# MSPM0G110X register map
Vendor: Texas Instruments; File version: This preliminary header file does not have a version number - build date: 2023-02-21 16:25:48
CPU: CM0 r0p1, little endian, MPU, no FPU, 3 interrupt priority bits
Registers are 32-bit, read-write, reset 0x0 unless marked. A register's access mark holds for its fields unless they carry their own. Offsets are from the block's base; [hi:lo] are bit positions; {n}, {i} and the like mark numbered series.

## TIMA0 — PERIPHERALREGION
Base 0x40860000
0x400 FSUB_0 — Subsciber Port 0
  [3:0] FSUB_0_CHANID — 0 = disconnected. 1-15 = connected to channelID = CHANID.
    0=FSUB_0_CHANID_UNCONNECTED (UNCONNECTED)
0x404 FSUB_1 — Subscriber Port 1
  [3:0] FSUB_1_CHANID — 0 = disconnected. 1-15 = connected to channelID = CHANID.
    0=FSUB_1_CHANID_UNCONNECTED (UNCONNECTED)
0x444 FPUB_0 — Publisher Port 0
  [3:0] FPUB_0_CHANID — 0 = disconnected. 1-15 = connected to channelID = CHANID.
    0=FPUB_0_CHANID_UNCONNECTED (UNCONNECTED)
0x448 FPUB_1 — Publisher Port 1
  [3:0] FPUB_1_CHANID — 0 = disconnected. 1-15 = connected to channelID = CHANID.
    0=FPUB_1_CHANID_UNCONNECTED (UNCONNECTED)
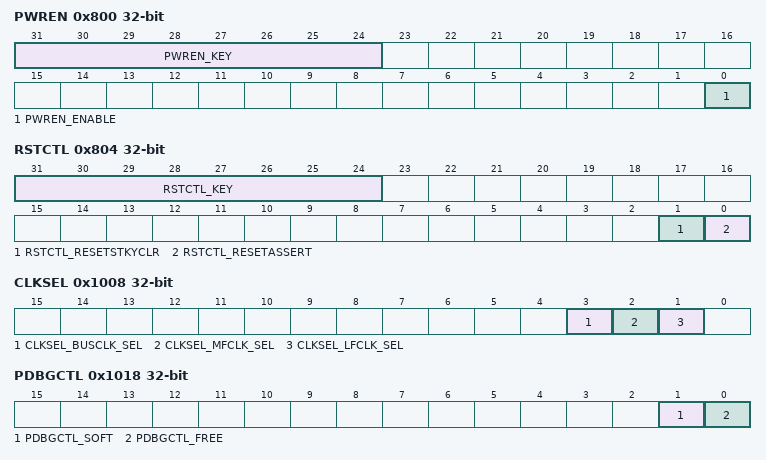
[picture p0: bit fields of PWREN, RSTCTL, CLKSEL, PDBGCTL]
0x800 PWREN — Power enable
  [31:24] PWREN_KEY wo — KEY to allow Power State Change
    38=PWREN_KEY_UNLOCK_W (_TO_UNLOCK_W_)
  [0] PWREN_ENABLE — Enable the power
    0=PWREN_ENABLE_DISABLE (DISABLE); 1=PWREN_ENABLE_ENABLE (ENABLE)
0x804 RSTCTL wo — Reset Control
  [31:24] RSTCTL_KEY — Unlock key
    177=RSTCTL_KEY_UNLOCK_W (_TO_UNLOCK_W_)
  [1] RSTCTL_RESETSTKYCLR — Clear the RESETSTKY bit in the STAT register
    0=RSTCTL_RESETSTKYCLR_NOP (NOP); 1=RSTCTL_RESETSTKYCLR_CLR (CLR)
  [0] RSTCTL_RESETASSERT — Assert reset to the peripheral
    0=RSTCTL_RESETASSERT_NOP (NOP); 1=RSTCTL_RESETASSERT_ASSERT (ASSERT)
0x814 STAT ro — Status Register
  [16] STAT_RESETSTKY — This bit indicates, if the peripheral was reset, since this bit was cleared by RESETSTKYCLR in the RSTCTL register
    0=STAT_RESETSTKY_NORES (NORES); 1=STAT_RESETSTKY_RESET (RESET)
0x1000 CLKDIV — Clock Divider
  [2:0] CLKDIV_RATIO — Selects divide ratio of module clock
    {v}=CLKDIV_RATIO_DIV_BY_{v+1} (DIV_BY_{v+1}) (v=0..7)
0x1008 CLKSEL — Clock Select for Ultra Low Power peripherals
  [3] CLKSEL_BUSCLK_SEL — Selects BUSCLK as clock source if enabled
    0=CLKSEL_BUSCLK_SEL_DISABLE (DISABLE); 1=CLKSEL_BUSCLK_SEL_ENABLE (ENABLE)
  [2] CLKSEL_MFCLK_SEL — Selects MFCLK as clock source if enabled
    0=CLKSEL_MFCLK_SEL_DISABLE (DISABLE); 1=CLKSEL_MFCLK_SEL_ENABLE (ENABLE)
  [1] CLKSEL_LFCLK_SEL — Selects LFCLK as clock source if enabled
    0=CLKSEL_LFCLK_SEL_DISABLE (DISABLE); 1=CLKSEL_LFCLK_SEL_ENABLE (ENABLE)
0x1018 PDBGCTL — Peripheral Debug Control
  [1] PDBGCTL_SOFT — Soft halt boundary control. This function is only available, if [FREE] is set to 'STOP'
    0=PDBGCTL_SOFT_IMMEDIATE (IMMEDIATE); 1=PDBGCTL_SOFT_DELAYED (DELAYED)
  [0] PDBGCTL_FREE — Free run control
    0=PDBGCTL_FREE_STOP (STOP); 1=PDBGCTL_FREE_RUN (RUN)
0x1020 IIDX ro — Interrupt index
  [7:0] IIDX_STAT — Interrupt index status
    0=IIDX_STAT_NO_INTR (NO_INTR); 1=IIDX_STAT_Z (Z); 2=IIDX_STAT_L (L); {v}=IIDX_STAT_CCD{v-5} (CCD{v-5}) (v=5..8); {v}=IIDX_STAT_CCU{v-9} (CCU{v-9}) (v=9..12); 13=IIDX_STAT_CCD4 (CCD4); 14=IIDX_STAT_CCD5 (CCD5); 15=IIDX_STAT_CCU4 (CCU4); 16=IIDX_STAT_CCU5 (CCU5); 25=IIDX_STAT_F (F); 26=IIDX_STAT_TOV (TOV); 27=IIDX_STAT_REPC (REPC); 28=IIDX_STAT_DC (DC); 29=IIDX_STAT_QEIERR (QEIERR)
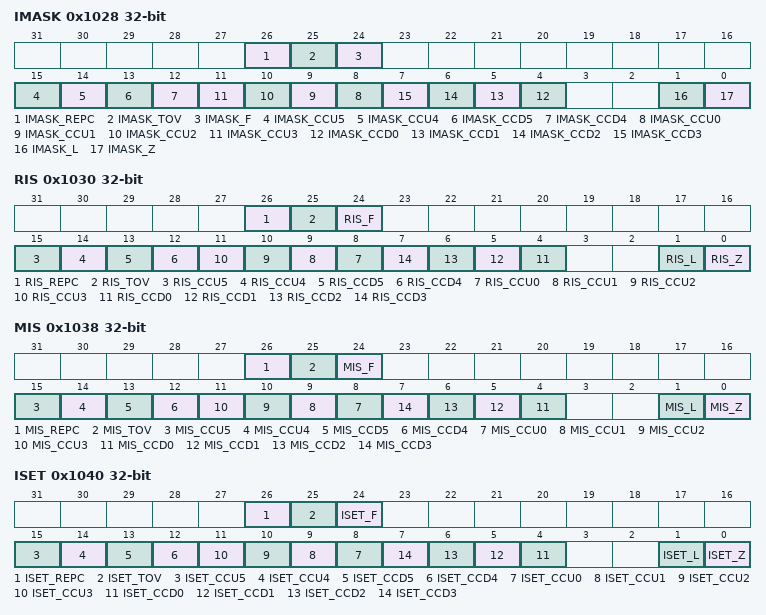
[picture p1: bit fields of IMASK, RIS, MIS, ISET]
0x1028 IMASK — Interrupt mask
  [26] IMASK_REPC — Repeat Counter Zero Event mask
    0=IMASK_REPC_CLR (CLR); 1=IMASK_REPC_SET (SET)
  [25] IMASK_TOV — Trigger Overflow Event mask
    0=IMASK_TOV_CLR (CLR); 1=IMASK_TOV_SET (SET)
  [24] IMASK_F — Fault Event mask
    0=IMASK_F_CLR (CLR); 1=IMASK_F_SET (SET)
  [15] IMASK_CCU5 — Compare UP event mask CCP5
    0=IMASK_CCU5_CLR (CLR); 1=IMASK_CCU5_SET (SET)
  [14] IMASK_CCU4 — Compare UP event mask CCP4
    0=IMASK_CCU4_CLR (CLR); 1=IMASK_CCU4_SET (SET)
  [13] IMASK_CCD5 — Compare DN event mask CCP5
    0=IMASK_CCD5_CLR (CLR); 1=IMASK_CCD5_SET (SET)
  [12] IMASK_CCD4 — Compare DN event mask CCP4
    0=IMASK_CCD4_CLR (CLR); 1=IMASK_CCD4_SET (SET)
  [n+8] IMASK_CCU{n} (n=0..3) — Capture or Compare UP event mask CCP{n}
    0=IMASK_CCU{n}_CLR (CLR); 1=IMASK_CCU{n}_SET (SET)
  [n+4] IMASK_CCD{n} (n=0..3) — Capture or Compare DN event mask CCP{n}
    0=IMASK_CCD{n}_CLR (CLR); 1=IMASK_CCD{n}_SET (SET)
  [1] IMASK_L — Load Event mask
    0=IMASK_L_CLR (CLR); 1=IMASK_L_SET (SET)
  [0] IMASK_Z — Zero Event mask
    0=IMASK_Z_CLR (CLR); 1=IMASK_Z_SET (SET)
0x1030 RIS ro — Raw interrupt status
  [26] RIS_REPC — Repeat Counter Zero
    0=RIS_REPC_CLR (CLR); 1=RIS_REPC_SET (SET)
  [25] RIS_TOV — Trigger overflow
    0=RIS_TOV_CLR (CLR); 1=RIS_TOV_SET (SET)
  [24] RIS_F — Fault
    0=RIS_F_CLR (CLR); 1=RIS_F_SET (SET)
  [15] RIS_CCU5 — Compare up event generated an interrupt CCP5
    0=RIS_CCU5_CLR (CLR); 1=RIS_CCU5_SET (SET)
  [14] RIS_CCU4 — Compare up event generated an interrupt CCU4
    0=RIS_CCU4_CLR (CLR); 1=RIS_CCU4_SET (SET)
  [13] RIS_CCD5 — Compare down event generated an interrupt CCD5
    0=RIS_CCD5_CLR (CLR); 1=RIS_CCD5_SET (SET)
  [12] RIS_CCD4 — Compare down event generated an interrupt CCD4
    0=RIS_CCD4_CLR (CLR); 1=RIS_CCD4_SET (SET)
  [n+8] RIS_CCU{n} (n=0..3) — Capture or compare up event generated an interrupt CCP{n}
    0=RIS_CCU{n}_CLR (CLR); 1=RIS_CCU{n}_SET (SET)
  [n+4] RIS_CCD{n} (n=0..3) — Capture or compare down event generated an interrupt CCP{n}
    0=RIS_CCD{n}_CLR (CLR); 1=RIS_CCD{n}_SET (SET)
  [1] RIS_L — Load event generated an interrupt.
    0=RIS_L_CLR (CLR); 1=RIS_L_SET (SET)
  [0] RIS_Z — Zero event generated an interrupt.
    0=RIS_Z_CLR (CLR); 1=RIS_Z_SET (SET)
0x1038 MIS ro — Masked interrupt status
  [26] MIS_REPC — Repeat Counter Zero
    0=MIS_REPC_CLR (CLR); 1=MIS_REPC_SET (SET)
  [25] MIS_TOV — Trigger overflow
    0=MIS_TOV_CLR (CLR); 1=MIS_TOV_SET (SET)
  [24] MIS_F — Fault
    0=MIS_F_CLR (CLR); 1=MIS_F_SET (SET)
  [15] MIS_CCU5 — Compare up event generated an interrupt CCP5
    0=MIS_CCU5_CLR (CLR); 1=MIS_CCU5_SET (SET)
  [14] MIS_CCU4 — Compare up event generated an interrupt CCP4
    0=MIS_CCU4_CLR (CLR); 1=MIS_CCU4_SET (SET)
  [13] MIS_CCD5 — Compare down event generated an interrupt CCP5
    0=MIS_CCD5_CLR (CLR); 1=MIS_CCD5_SET (SET)
  [12] MIS_CCD4 — Compare down event generated an interrupt CCP4
    0=MIS_CCD4_CLR (CLR); 1=MIS_CCD4_SET (SET)
  [n+8] MIS_CCU{n} (n=0..3) — Capture or compare up event generated an interrupt CCP{n}
    0=MIS_CCU{n}_CLR (CLR); 1=MIS_CCU{n}_SET (SET)
  [n+4] MIS_CCD{n} (n=0..3) — Capture or compare down event generated an interrupt CCP{n}
    0=MIS_CCD{n}_CLR (CLR); 1=MIS_CCD{n}_SET (SET)
  [1] MIS_L — Load event generated an interrupt.
    0=MIS_L_CLR (CLR); 1=MIS_L_SET (SET)
  [0] MIS_Z — Zero event generated an interrupt.
    0=MIS_Z_CLR (CLR); 1=MIS_Z_SET (SET)
0x1040 ISET wo — Interrupt set
  [26] ISET_REPC — Repeat Counter Zero event SET
    0=ISET_REPC_NO_EFFECT (NO_EFFECT); 1=ISET_REPC_SET (SET)
  [25] ISET_TOV — Trigger Overflow event SET
    0=ISET_TOV_NO_EFFECT (NO_EFFECT); 1=ISET_TOV_SET (SET)
  [24] ISET_F — Fault event SET
    0=ISET_F_NO_EFFECT (NO_EFFECT); 1=ISET_F_SET (SET)
  [15] ISET_CCU5 — Compare up event 5 SET
    0=ISET_CCU5_NO_EFFECT (NO_EFFECT); 1=ISET_CCU5_SET (SET)
  [14] ISET_CCU4 — Compare up event 4 SET
    0=ISET_CCU4_NO_EFFECT (NO_EFFECT); 1=ISET_CCU4_SET (SET)
  [13] ISET_CCD5 — Compare down event 5 SET
    0=ISET_CCD5_NO_EFFECT (NO_EFFECT); 1=ISET_CCD5_SET (SET)
  [12] ISET_CCD4 — Compare down event 4 SET
    0=ISET_CCD4_NO_EFFECT (NO_EFFECT); 1=ISET_CCD4_SET (SET)
  [n+8] ISET_CCU{n} (n=0..3) — Capture or compare up event SET
    0=ISET_CCU{n}_NO_EFFECT (NO_EFFECT); 1=ISET_CCU{n}_SET (SET)
  [n+4] ISET_CCD{n} (n=0..3) — Capture or compare down event SET
    0=ISET_CCD{n}_NO_EFFECT (NO_EFFECT); 1=ISET_CCD{n}_SET (SET)
  [1] ISET_L — Load event SET
    0=ISET_L_NO_EFFECT (NO_EFFECT); 1=ISET_L_SET (SET)
  [0] ISET_Z — Zero event SET
    0=ISET_Z_NO_EFFECT (NO_EFFECT); 1=ISET_Z_SET (SET)
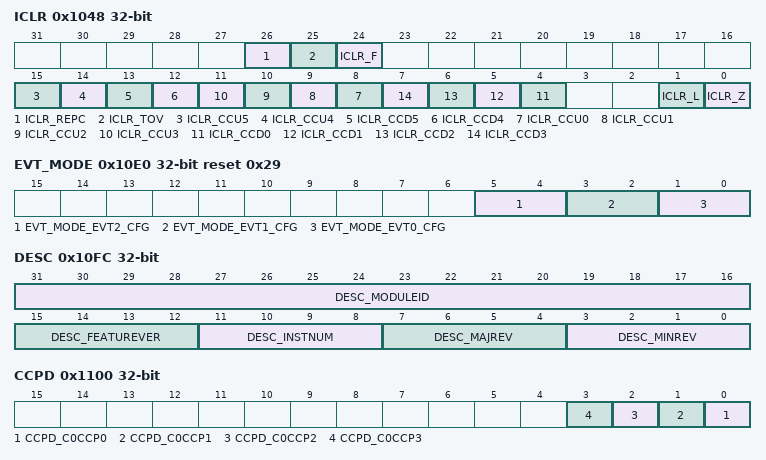
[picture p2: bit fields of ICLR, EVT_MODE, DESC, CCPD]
0x1048 ICLR wo — Interrupt clear
  [26] ICLR_REPC — Repeat Counter Zero event CLEAR
    0=ICLR_REPC_NO_EFFECT (NO_EFFECT); 1=ICLR_REPC_CLR (CLR)
  [25] ICLR_TOV — Trigger Overflow event CLEAR
    0=ICLR_TOV_NO_EFFECT (NO_EFFECT); 1=ICLR_TOV_CLR (CLR)
  [24] ICLR_F — Fault event CLEAR
    0=ICLR_F_NO_EFFECT (NO_EFFECT); 1=ICLR_F_CLR (CLR)
  [15] ICLR_CCU5 — Compare up event 5 CLEAR
    0=ICLR_CCU5_NO_EFFECT (NO_EFFECT); 1=ICLR_CCU5_CLR (CLR)
  [14] ICLR_CCU4 — Compare up event 4 CLEAR
    0=ICLR_CCU4_NO_EFFECT (NO_EFFECT); 1=ICLR_CCU4_CLR (CLR)
  [13] ICLR_CCD5 — Compare down event 5 CLEAR
    0=ICLR_CCD5_NO_EFFECT (NO_EFFECT); 1=ICLR_CCD5_CLR (CLR)
  [12] ICLR_CCD4 — Compare down event 4 CLEAR
    0=ICLR_CCD4_NO_EFFECT (NO_EFFECT); 1=ICLR_CCD4_CLR (CLR)
  [n+8] ICLR_CCU{n} (n=0..3) — Capture or compare up event CLEAR
    0=ICLR_CCU{n}_NO_EFFECT (NO_EFFECT); 1=ICLR_CCU{n}_CLR (CLR)
  [n+4] ICLR_CCD{n} (n=0..3) — Capture or compare down event CLEAR
    0=ICLR_CCD{n}_NO_EFFECT (NO_EFFECT); 1=ICLR_CCD{n}_CLR (CLR)
  [1] ICLR_L — Load event CLEAR
    0=ICLR_L_NO_EFFECT (NO_EFFECT); 1=ICLR_L_CLR (CLR)
  [0] ICLR_Z — Zero event CLEAR
    0=ICLR_Z_NO_EFFECT (NO_EFFECT); 1=ICLR_Z_CLR (CLR)
0x10E0 EVT_MODE reset 0x29 — Event Mode
  [5:4] EVT_MODE_EVT2_CFG ro — Event line mode select for event corresponding to [IPSTANDARD.INT_EVENT][1]
    0=EVT_MODE_EVT2_CFG_DISABLE (DISABLE); 1=EVT_MODE_EVT2_CFG_SOFTWARE (SOFTWARE); 2=EVT_MODE_EVT2_CFG_HARDWARE (HARDWARE)
  [3:2] EVT_MODE_EVT1_CFG ro — Event line mode select for event corresponding to [IPSTANDARD.INT_EVENT][1]
    0=EVT_MODE_EVT1_CFG_DISABLE (DISABLE); 1=EVT_MODE_EVT1_CFG_SOFTWARE (SOFTWARE); 2=EVT_MODE_EVT1_CFG_HARDWARE (HARDWARE)
  [1:0] EVT_MODE_EVT0_CFG ro — Event line mode select for event corresponding to [IPSTANDARD.INT_EVENT][0]
    0=EVT_MODE_EVT0_CFG_DISABLE (DISABLE); 1=EVT_MODE_EVT0_CFG_SOFTWARE (SOFTWARE); 2=EVT_MODE_EVT0_CFG_HARDWARE (HARDWARE)
0x10FC DESC ro — Module Description
  [31:16] DESC_MODULEID — Module identification contains a unique peripheral identification number. The assignments are maintained in a central database for all of the platform modules to ensure uniqueness.
  [15:12] DESC_FEATUREVER — Feature Set for the module *instance*
  [11:8] DESC_INSTNUM — Instance Number within the device. This will be a parameter to the RTL for modules that can have multiple instances
  [7:4] DESC_MAJREV — Major rev of the IP
  [3:0] DESC_MINREV — Minor rev of the IP
0x1100 CCPD — CCP Direction
  [n] CCPD_C0CCP{n} (n=0..3) — Counter CCP{n}
    0=CCPD_C0CCP{n}_INPUT (INPUT); 1=CCPD_C0CCP{n}_OUTPUT (OUTPUT)
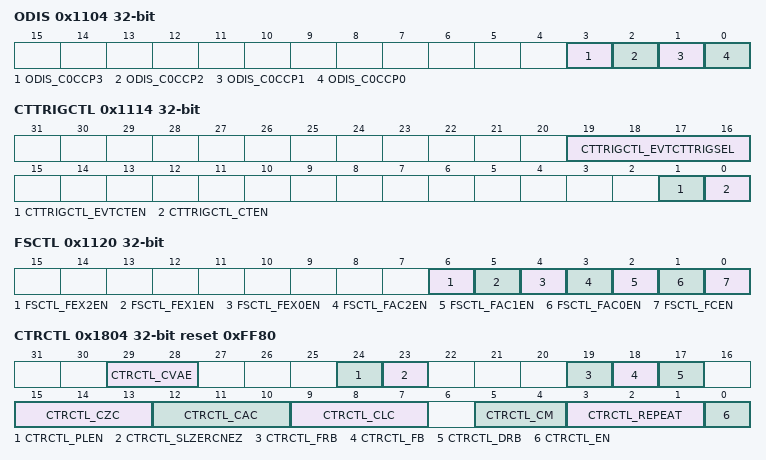
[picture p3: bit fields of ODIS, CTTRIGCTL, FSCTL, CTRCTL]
0x1104 ODIS — Output Disable
  [3] ODIS_C0CCP3 — Counter CCP3 Disable Mask Defines whether CCP3 of Counter n is forced low or not
    0=ODIS_C0CCP3_CCP_OUTPUT_OCTL (CCP_OUTPUT_OCTL); 1=ODIS_C0CCP3_CCP_OUTPUT_LOW (CCP_OUTPUT_LOW)
  [2] ODIS_C0CCP2 — Counter CCP2 Disable Mask Defines whether CCP2 of Counter n is forced low or not
    0=ODIS_C0CCP2_CCP_OUTPUT_OCTL (CCP_OUTPUT_OCTL); 1=ODIS_C0CCP2_CCP_OUTPUT_LOW (CCP_OUTPUT_LOW)
  [1] ODIS_C0CCP1 — Counter CCP1 Disable Mask Defines whether CCP0 of Counter n is forced low or not
    0=ODIS_C0CCP1_CCP_OUTPUT_OCTL (CCP_OUTPUT_OCTL); 1=ODIS_C0CCP1_CCP_OUTPUT_LOW (CCP_OUTPUT_LOW)
  [0] ODIS_C0CCP0 — Counter CCP0 Disable Mask Defines whether CCP0 of Counter n is forced low or not
    0=ODIS_C0CCP0_CCP_OUTPUT_OCTL (CCP_OUTPUT_OCTL); 1=ODIS_C0CCP0_CCP_OUTPUT_LOW (CCP_OUTPUT_LOW)
0x1108 CCLKCTL — Counter Clock Control Register
  [0] CCLKCTL_CLKEN — Clock Enable Disables the clock gating to the module. SW has to explicitly program the value to 0 to gate the clock.
    0=CCLKCTL_CLKEN_DISABLED (DISABLED); 1=CCLKCTL_CLKEN_ENABLED (ENABLED)
0x110C CPS — Clock Prescale Register
  [7:0] CPS_PCNT — Pre-Scale Count This field specifies the pre-scale count value. The selected TIMCLK source is divided by a value of (PCNT+1). A PCNT value of 0 divides TIMCLK by 1, effectively bypassing the divider. A PCNT value of greater than 0 divides the TIMCLK source generating a slower clock
0x1110 CPSV ro — Clock prescale count status register
  [7:0] CPSV_CPSVAL — Current Prescale Count Value
0x1114 CTTRIGCTL — Timer Cross Trigger Control Register
  [19:16] CTTRIGCTL_EVTCTTRIGSEL — Used to Select the subscriber port that should be used for input cross trigger. Refer Figure 8 Cross Trigger Generation Path
    0=CTTRIGCTL_EVTCTTRIGSEL_FSUB0 (FSUB0); 1=CTTRIGCTL_EVTCTTRIGSEL_FSUB1 (FSUB1); 2=CTTRIGCTL_EVTCTTRIGSEL_Z (Z); 3=CTTRIGCTL_EVTCTTRIGSEL_L (L); {v}=CTTRIGCTL_EVTCTTRIGSEL_CCD{v-4} (CCD{v-4}) (v=4..7); {v}=CTTRIGCTL_EVTCTTRIGSEL_CCU{v-8} (CCU{v-8}) (v=8..11)
  [1] CTTRIGCTL_EVTCTEN — Enable the Input Trigger Conditions to the Timer module as a condition for Cross Triggers. Refer Figure 8 Cross Trigger Generation Path
    0=CTTRIGCTL_EVTCTEN_DISABLED (DISABLED); 1=CTTRIGCTL_EVTCTEN_ENABLE (ENABLE)
  [0] CTTRIGCTL_CTEN — Timer Cross trigger enable. This field is used to enable whether the SW or HW logic can generate a timer cross trigger event in the system. These cross triggers are connected to the respective timer trigger in of the other timer IPs in the SOC power domain. The timer cross trigger is essentially the combined logic of the HW and SW conditions controlling EN bit in the CTRCTL register.
    0=CTTRIGCTL_CTEN_DISABLED (DISABLED); 1=CTTRIGCTL_CTEN_ENABLE (ENABLE)
0x111C CTTRIG wo — Timer Cross Trigger Register
  [0] CTTRIG_TRIG — Generate Cross Trigger This bit when programmed will generate a synchronized trigger condition all the cross trigger enabled Timer instances including current timer instance.
    0=CTTRIG_TRIG_DISABLED (DISABLED); 1=CTTRIG_TRIG_GENERATE (GENERATE)
0x1120 FSCTL — Fault Source Control
  [6] FSCTL_FEX2EN — This field controls whether the fault caused by external fault pin2 is enable. 0: DISABLE 1: ENABLE
    0=FSCTL_FEX2EN_DISABLE (DISABLE); 1=FSCTL_FEX2EN_ENABLE (ENABLE)
  [5] FSCTL_FEX1EN — This field controls whether the fault caused by external fault pin1 is enable. 0: DISABLE 1: ENABLE
    0=FSCTL_FEX1EN_DISABLE (DISABLE); 1=FSCTL_FEX1EN_ENABLE (ENABLE)
  [4] FSCTL_FEX0EN — This field controls whether the fault caused by external fault pin0 is enable. 0: DISABLE 1: ENABLE
    0=FSCTL_FEX0EN_DISABLE (DISABLE); 1=FSCTL_FEX0EN_ENABLE (ENABLE)
  [3] FSCTL_FAC2EN — This field controls whether the fault signal detected by the analog comparator2 is enable 0: DISABLE 1: ENABLE
    0=FSCTL_FAC2EN_DISABLE (DISABLE); 1=FSCTL_FAC2EN_ENABLE (ENABLE)
  [2] FSCTL_FAC1EN — This field controls whether the fault signal detected by the analog comparator1 is enable 0: DISABLE 1: ENABLE
    0=FSCTL_FAC1EN_DISABLE (DISABLE); 1=FSCTL_FAC1EN_ENABLE (ENABLE)
  [1] FSCTL_FAC0EN — This field controls whether the fault signal detected by the analog comparator0 is enable 0: DISABLE 1: ENABLE
    0=FSCTL_FAC0EN_DISABLE (DISABLE); 1=FSCTL_FAC0EN_ENABLE (ENABLE)
  [0] FSCTL_FCEN — This field controls whether the fault caused by the system clock fault is enable. 0: DISABLE 1: ENABLE
    0=FSCTL_FCEN_DISABLE (DISABLE); 1=FSCTL_FCEN_ENABLE (ENABLE)
0x1124 GCTL — Shadow to active load mask
  [0] GCTL_SHDWLDEN — Enables shadow to active load of bufferred registers and register fields.
    0=GCTL_SHDWLDEN_DISABLE (DISABLE); 1=GCTL_SHDWLDEN_ENABLE (ENABLE)
0x1800 CTR — Counter Register
  [15:0] CTR_CCTR — Current Counter value
0x1804 CTRCTL reset 0xFF80 — Counter Control Register
  [29:28] CTRCTL_CVAE — Counter Value After Enable. This field specifies the initialization condition of the counter when the EN bit is changed from 0 to 1 by a write to the CTRCTL register. Note that an external event can also cause the EN bit to go active.
    0=CTRCTL_CVAE_LDVAL (LDVAL); 1=CTRCTL_CVAE_NOCHANGE (NOCHANGE); 2=CTRCTL_CVAE_ZEROVAL (ZEROVAL)
  [24] CTRCTL_PLEN — Phase Load Enable. This bit allows the timer to have phase load feature.
    0=CTRCTL_PLEN_DISABLED (DISABLED); 1=CTRCTL_PLEN_ENABLED (ENABLED)
  [23] CTRCTL_SLZERCNEZ — Suppress Load and Zero Events if Repeat Counter is Not Equal to Zero. This bit suppresses the generation of the Z (zero) and L (load) events from the counter when the repeat counter (RC) value is not 0.
    0=CTRCTL_SLZERCNEZ_DISABLED (DISABLED); 1=CTRCTL_SLZERCNEZ_ENABLED (ENABLED)
  [19] CTRCTL_FRB — Fault Resume Behavior This bit specifies what the device does following the release/exit of fault condition.
    0=CTRCTL_FRB_RESUME (RESUME); 1=CTRCTL_FRB_CVAE_ACTION (CVAE_ACTION)
  [18] CTRCTL_FB — Fault Behavior This bit specifies whether the counter continues running or suspends during a fault mode. There is a separate control under REPEAT to indicate whether counting is to suspend at next Counter==0
    0=CTRCTL_FB_CONT_COUNT (CONT_COUNT); 1=CTRCTL_FB_SUSP_COUNT (SUSP_COUNT)
  [17] CTRCTL_DRB — Debug Resume Behavior This bit specifies what the device does following the release/exit of debug mode.
    0=CTRCTL_DRB_RESUME (RESUME); 1=CTRCTL_DRB_CVAE_ACTION (CVAE_ACTION)
  [15:13] CTRCTL_CZC — Counter Zero Control This field specifies what controls the counter operation with respect to zeroing the counter value. Encodings 1-3 are present based on the CCPC parameter value. Bits 4-5 are present based on the HQEI parameter value. Any encodings not provided are documented as reserved.
    {v}=CTRCTL_CZC_CCCTL{v}_ZCOND (CCCTL{v}_ZCOND) (v=0..3); 4=CTRCTL_CZC_QEI_2INP (QEI_2INP); 5=CTRCTL_CZC_QEI_3INP (QEI_3INP)
  [12:10] CTRCTL_CAC — Counter Advance Control. This field specifies what controls the counter operation with respect to advancing (incrementing or decrementing) the counter value. Encodings 1-3 are present based on the CCPC parameter value. Bits 4-5 are present based on the HQEI parameter value. Any encodings not provided are documented as reserved.
    {v}=CTRCTL_CAC_CCCTL{v}_ACOND (CCCTL{v}_ACOND) (v=0..3); 4=CTRCTL_CAC_QEI_2INP (QEI_2INP); 5=CTRCTL_CAC_QEI_3INP (QEI_3INP)
  [9:7] CTRCTL_CLC — Counter Load Control. This field specifies what controls the counter operation with respect to setting the counter to the LD register value. Encodings 1-3 are present based on the CCPC parameter value. Bits 4-5 are present based on the HQEI parameter value. Any encodings not provided are documented as reserved.
    {v}=CTRCTL_CLC_CCCTL{v}_LCOND (CCCTL{v}_LCOND) (v=0..3); 4=CTRCTL_CLC_QEI_2INP (QEI_2INP); 5=CTRCTL_CLC_QEI_3INP (QEI_3INP)
  [5:4] CTRCTL_CM — Count Mode
    0=CTRCTL_CM_DOWN (DOWN); 1=CTRCTL_CM_UP_DOWN (UP_DOWN); 2=CTRCTL_CM_UP (UP)
  [3:1] CTRCTL_REPEAT — Repeat. The repeat bit controls whether the counter continues to advance following a zero event, or the exiting of a debug or fault condition. If counting down, a zero event is followed by a load at the next advance condition. If counting up-down, a zero event is followed by an advance event (+1). The intent of encoding 3 is that if the debug condition is in effect, the generation of the load pulse is deferred until the debug condition is over. This allows the counter to reach zero before counting is suspended.
    {v}=CTRCTL_REPEAT_REPEAT_{v} (REPEAT_{v}) (v=0..4)
  [0] CTRCTL_EN — Counter Enable. This bit allows the timer to advance This bit is automatically cleared if REPEAT=0 (do not automatically reload) and the counter value equals zero. CPU Write: A register write that sets the EN bit, the counter value is set per the CVAE value. Hardware: This bit may also be set as the result of an LCOND or ZCOND condition being met and the counter value changed to the load value or zero value, respectively.
    0=CTRCTL_EN_DISABLED (DISABLED); 1=CTRCTL_EN_ENABLED (ENABLED)
0x1808 LOAD
  [15:0] LOAD_LD — Load Value
{0x1810+4i} CC_01[{i}] (i=0..1) — Capture or Compare Register 0 to Capture or Compare Register 1
  [15:0] CC_01_CCVAL — Capture or compare value
{0x1818+4i} CC_23[{i}] (i=0..1) — Capture or Compare Register 0 to Capture or Compare Register 1
  [15:0] CC_23_CCVAL — Capture or compare value
{0x1820+4i} CC_45[{i}] (i=0..1) — Compare Register 4 to Compare Register 5
  [15:0] CC_45_CCVAL — Capture or compare value
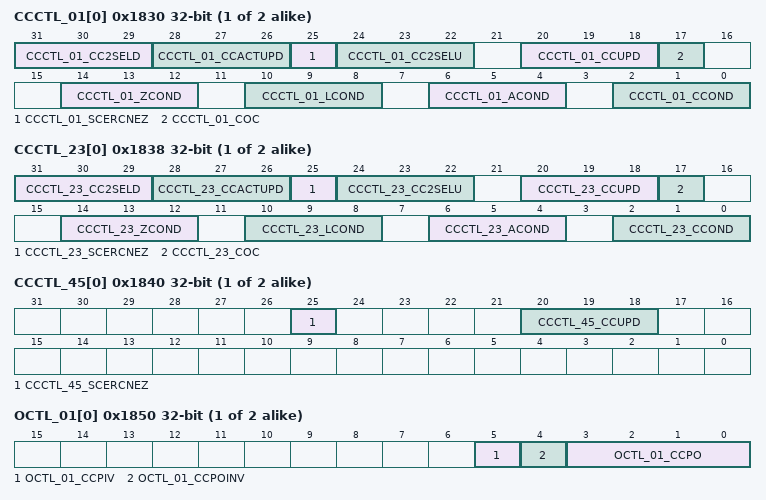
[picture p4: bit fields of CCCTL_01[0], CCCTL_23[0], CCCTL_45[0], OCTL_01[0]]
{0x1830+4i} CCCTL_01[{i}] (i=0..1) — Capture or Compare Control Registers
  [31:29] CCCTL_01_CC2SELD — Selects the source second CCD event.
    {v}=CCCTL_01_CC2SELD_SEL_CCD{v} (SEL_CCD{v}) (v=0..5)
  [28:26] CCCTL_01_CCACTUPD — CCACT shadow register Update Method This field controls how updates to the CCCACT shadow register are performed
    0=CCCTL_01_CCACTUPD_IMMEDIATELY (IMMEDIATELY); 1=CCCTL_01_CCACTUPD_ZERO_EVT (ZERO_EVT); 2=CCCTL_01_CCACTUPD_COMPARE_DOWN_EVT (COMPARE_DOWN_EVT); 3=CCCTL_01_CCACTUPD_COMPARE_UP_EVT (COMPARE_UP_EVT); 4=CCCTL_01_CCACTUPD_ZERO_LOAD_EVT (ZERO_LOAD_EVT); 5=CCCTL_01_CCACTUPD_ZERO_RC_ZERO_EVT (ZERO_RC_ZERO_EVT); 6=CCCTL_01_CCACTUPD_TRIG (TRIG)
  [25] CCCTL_01_SCERCNEZ — Suppress Compare Event if Repeat Counter is Not Equal to Zero This bit suppresses the generation of the compare (CCD, CCU and RC) events from the counter when the repeat counter (RC) value is not 0.
    0=CCCTL_01_SCERCNEZ_DISABLED (DISABLED); 1=CCCTL_01_SCERCNEZ_ENABLED (ENABLED)
  [24:22] CCCTL_01_CC2SELU — Selects the source second CCU event.
    {v}=CCCTL_01_CC2SELU_SEL_CCU{v} (SEL_CCU{v}) (v=0..5)
  [20:18] CCCTL_01_CCUPD — Capture and Compare Update Method This field controls how updates to the pipelined capture and compare register are performed (when operating in compare mode, COC=0).
    0=CCCTL_01_CCUPD_IMMEDIATELY (IMMEDIATELY); 1=CCCTL_01_CCUPD_ZERO_EVT (ZERO_EVT); 2=CCCTL_01_CCUPD_COMPARE_DOWN_EVT (COMPARE_DOWN_EVT); 3=CCCTL_01_CCUPD_COMPARE_UP_EVT (COMPARE_UP_EVT); 4=CCCTL_01_CCUPD_ZERO_LOAD_EVT (ZERO_LOAD_EVT); 5=CCCTL_01_CCUPD_ZERO_RC_ZERO_EVT (ZERO_RC_ZERO_EVT); 6=CCCTL_01_CCUPD_TRIG (TRIG)
  [17] CCCTL_01_COC — Capture or Compare. #br# Specifies whether the corresponding CC register is used as a capture register or a compare register (never both).
    0=CCCTL_01_COC_COMPARE (COMPARE); 1=CCCTL_01_COC_CAPTURE (CAPTURE)
  [14:12] CCCTL_01_ZCOND — Zero Condition. #br# This field specifies the condition that generates a zero pulse. 4h-Fh = Reserved
    1=CCCTL_01_ZCOND_CC_TRIG_RISE (CC_TRIG_RISE); 2=CCCTL_01_ZCOND_CC_TRIG_FALL (CC_TRIG_FALL); 3=CCCTL_01_ZCOND_CC_TRIG_EDGE (CC_TRIG_EDGE)
  [10:8] CCCTL_01_LCOND — Load Condition. #br# Specifies the condition that generates a load pulse. 4h-Fh = Reserved
    1=CCCTL_01_LCOND_CC_TRIG_RISE (CC_TRIG_RISE); 2=CCCTL_01_LCOND_CC_TRIG_FALL (CC_TRIG_FALL); 3=CCCTL_01_LCOND_CC_TRIG_EDGE (CC_TRIG_EDGE)
  [6:4] CCCTL_01_ACOND — Advance Condition. #br# Specifies the condition that generates an advance pulse. 6h-Fh = Reserved
    0=CCCTL_01_ACOND_TIMCLK (TIMCLK); 1=CCCTL_01_ACOND_CC_TRIG_RISE (CC_TRIG_RISE); 2=CCCTL_01_ACOND_CC_TRIG_FALL (CC_TRIG_FALL); 3=CCCTL_01_ACOND_CC_TRIG_EDGE (CC_TRIG_EDGE); 5=CCCTL_01_ACOND_CC_TRIG_HIGH (CC_TRIG_HIGH)
  [2:0] CCCTL_01_CCOND — Capture Condition. #br# Specifies the condition that generates a capture pulse. 4h-Fh = Reserved
    0=CCCTL_01_CCOND_NOCAPTURE (NOCAPTURE); 1=CCCTL_01_CCOND_CC_TRIG_RISE (CC_TRIG_RISE); 2=CCCTL_01_CCOND_CC_TRIG_FALL (CC_TRIG_FALL); 3=CCCTL_01_CCOND_CC_TRIG_EDGE (CC_TRIG_EDGE)
{0x1838+4i} CCCTL_23[{i}] (i=0..1) — Capture or Compare Control Registers
  [31:29] CCCTL_23_CC2SELD — Selects the source second CCD event.
    {v}=CCCTL_23_CC2SELD_SEL_CCD{v} (SEL_CCD{v}) (v=0..5)
  [28:26] CCCTL_23_CCACTUPD — CCACT shadow register Update Method This field controls how updates to the CCCACT shadow register are performed
    0=CCCTL_23_CCACTUPD_IMMEDIATELY (IMMEDIATELY); 1=CCCTL_23_CCACTUPD_ZERO_EVT (ZERO_EVT); 2=CCCTL_23_CCACTUPD_COMPARE_DOWN_EVT (COMPARE_DOWN_EVT); 3=CCCTL_23_CCACTUPD_COMPARE_UP_EVT (COMPARE_UP_EVT); 4=CCCTL_23_CCACTUPD_ZERO_LOAD_EVT (ZERO_LOAD_EVT); 5=CCCTL_23_CCACTUPD_ZERO_RC_ZERO_EVT (ZERO_RC_ZERO_EVT); 6=CCCTL_23_CCACTUPD_TRIG (TRIG)
  [25] CCCTL_23_SCERCNEZ — Suppress Compare Event if Repeat Counter is Not Equal to Zero This bit suppresses the generation of the compare (CCD, CCU and RC) events from the counter when the repeat counter (RCn) value is not 0.
    0=CCCTL_23_SCERCNEZ_DISABLED (DISABLED); 1=CCCTL_23_SCERCNEZ_ENABLED (ENABLED)
  [24:22] CCCTL_23_CC2SELU — Selects the source second CCU event.
    {v}=CCCTL_23_CC2SELU_SEL_CCU{v} (SEL_CCU{v}) (v=0..5)
  [20:18] CCCTL_23_CCUPD — Capture and Compare Update Method This field controls how updates to the pipelined capture and compare register are performed (when operating in compare mode, COC=0).
    0=CCCTL_23_CCUPD_IMMEDIATELY (IMMEDIATELY); 1=CCCTL_23_CCUPD_ZERO_EVT (ZERO_EVT); 2=CCCTL_23_CCUPD_COMPARE_DOWN_EVT (COMPARE_DOWN_EVT); 3=CCCTL_23_CCUPD_COMPARE_UP_EVT (COMPARE_UP_EVT); 4=CCCTL_23_CCUPD_ZERO_LOAD_EVT (ZERO_LOAD_EVT); 5=CCCTL_23_CCUPD_ZERO_RC_ZERO_EVT (ZERO_RC_ZERO_EVT); 6=CCCTL_23_CCUPD_TRIG (TRIG)
  [17] CCCTL_23_COC — Capture or Compare. #br# Specifies whether the corresponding CC register is used as a capture register or a compare register (never both).
    0=CCCTL_23_COC_COMPARE (COMPARE); 1=CCCTL_23_COC_CAPTURE (CAPTURE)
  [14:12] CCCTL_23_ZCOND — Zero Condition. #br# This field specifies the condition that generates a zero pulse. 4h-Fh = Reserved
    1=CCCTL_23_ZCOND_CC_TRIG_RISE (CC_TRIG_RISE); 2=CCCTL_23_ZCOND_CC_TRIG_FALL (CC_TRIG_FALL); 3=CCCTL_23_ZCOND_CC_TRIG_EDGE (CC_TRIG_EDGE)
  [10:8] CCCTL_23_LCOND — Load Condition. #br# Specifies the condition that generates a load pulse. 4h-Fh = Reserved
    1=CCCTL_23_LCOND_CC_TRIG_RISE (CC_TRIG_RISE); 2=CCCTL_23_LCOND_CC_TRIG_FALL (CC_TRIG_FALL); 3=CCCTL_23_LCOND_CC_TRIG_EDGE (CC_TRIG_EDGE)
  [6:4] CCCTL_23_ACOND — Advance Condition. #br# Specifies the condition that generates an advance pulse. 6h-Fh = Reserved
    0=CCCTL_23_ACOND_TIMCLK (TIMCLK); 1=CCCTL_23_ACOND_CC_TRIG_RISE (CC_TRIG_RISE); 2=CCCTL_23_ACOND_CC_TRIG_FALL (CC_TRIG_FALL); 3=CCCTL_23_ACOND_CC_TRIG_EDGE (CC_TRIG_EDGE); 5=CCCTL_23_ACOND_CC_TRIG_HIGH (CC_TRIG_HIGH)
  [2:0] CCCTL_23_CCOND — Capture Condition. #br# Specifies the condition that generates a capture pulse. 4h-Fh = Reserved
    0=CCCTL_23_CCOND_NOCAPTURE (NOCAPTURE); 1=CCCTL_23_CCOND_CC_TRIG_RISE (CC_TRIG_RISE); 2=CCCTL_23_CCOND_CC_TRIG_FALL (CC_TRIG_FALL); 3=CCCTL_23_CCOND_CC_TRIG_EDGE (CC_TRIG_EDGE)
{0x1840+4i} CCCTL_45[{i}] (i=0..1) — Capture or Compare Control Registers
  [25] CCCTL_45_SCERCNEZ — Suppress Compare Event if Repeat Counter is Not Equal to Zero This bit suppresses the generation of the compare (CCD, CCU and RC) events from the counter when the repeat counter (RC) value is not 0.
    0=CCCTL_45_SCERCNEZ_DISABLED (DISABLED); 1=CCCTL_45_SCERCNEZ_ENABLED (ENABLED)
  [20:18] CCCTL_45_CCUPD — Capture and Compare Update Method This field controls how updates to the pipelined capture and compare register are performed (when operating in compare mode, COC=0).
    0=CCCTL_45_CCUPD_IMMEDIATELY (IMMEDIATELY); 1=CCCTL_45_CCUPD_ZERO_EVT (ZERO_EVT); 2=CCCTL_45_CCUPD_COMPARE_DOWN_EVT (COMPARE_DOWN_EVT); 3=CCCTL_45_CCUPD_COMPARE_UP_EVT (COMPARE_UP_EVT); 4=CCCTL_45_CCUPD_ZERO_LOAD_EVT (ZERO_LOAD_EVT); 5=CCCTL_45_CCUPD_ZERO_RC_ZERO_EVT (ZERO_RC_ZERO_EVT); 6=CCCTL_45_CCUPD_TRIG (TRIG)
{0x1850+4i} OCTL_01[{i}] (i=0..1) — CCP Output Control Registers
  [5] OCTL_01_CCPIV — CCP Initial Value This bit specifies the logical value put on the signal generator state while the counter is disabled (CTRCTL.EN == 0).
    0=OCTL_01_CCPIV_LOW (LOW); 1=OCTL_01_CCPIV_HIGH (HIGH)
  [4] OCTL_01_CCPOINV — CCP Output Invert The output as selected by CCPO is conditionally inverted.
    0=OCTL_01_CCPOINV_NOINV (NOINV); 1=OCTL_01_CCPOINV_INV (INV)
  [3:0] OCTL_01_CCPO — CCP Output Source
    0=OCTL_01_CCPO_FUNCVAL (FUNCVAL); 1=OCTL_01_CCPO_LOAD (LOAD); 2=OCTL_01_CCPO_CMPVAL (CMPVAL); 4=OCTL_01_CCPO_ZERO (ZERO); 5=OCTL_01_CCPO_CAPCOND (CAPCOND); 6=OCTL_01_CCPO_FAULTCOND (FAULTCOND); 8=OCTL_01_CCPO_CC0_MIRROR_ALL (CC0_MIRROR_ALL); 9=OCTL_01_CCPO_CC1_MIRROR_ALL (CC1_MIRROR_ALL); 12=OCTL_01_CCPO_DEADBAND (DEADBAND); 13=OCTL_01_CCPO_CNTDIR (CNTDIR)
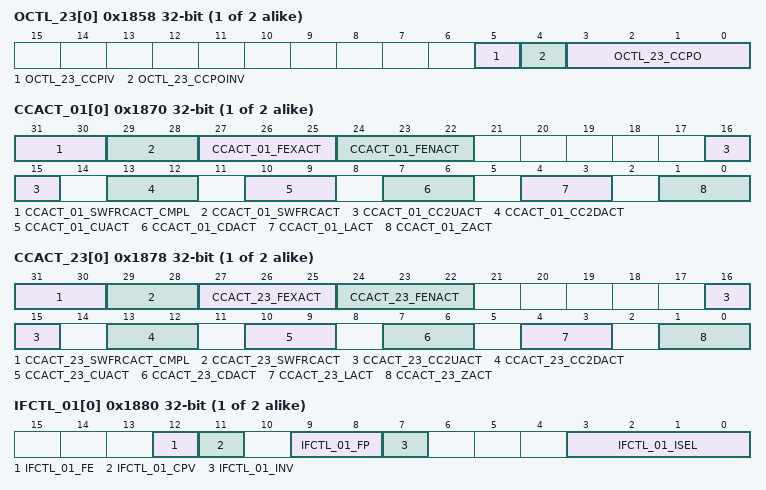
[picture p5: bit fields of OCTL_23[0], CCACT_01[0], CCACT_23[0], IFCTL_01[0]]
{0x1858+4i} OCTL_23[{i}] (i=0..1) — CCP Output Control Registers
  [5] OCTL_23_CCPIV — CCP Initial Value This bit specifies the logical value put on the signal generator state while the counter is disabled (CTRCTL.EN == 0).
    0=OCTL_23_CCPIV_LOW (LOW); 1=OCTL_23_CCPIV_HIGH (HIGH)
  [4] OCTL_23_CCPOINV — CCP Output Invert The output as selected by CCPO is conditionally inverted.
    0=OCTL_23_CCPOINV_NOINV (NOINV); 1=OCTL_23_CCPOINV_INV (INV)
  [3:0] OCTL_23_CCPO — CCP Output Source
    0=OCTL_23_CCPO_FUNCVAL (FUNCVAL); 1=OCTL_23_CCPO_LOAD (LOAD); 2=OCTL_23_CCPO_CMPVAL (CMPVAL); 4=OCTL_23_CCPO_ZERO (ZERO); 5=OCTL_23_CCPO_CAPCOND (CAPCOND); 6=OCTL_23_CCPO_FAULTCOND (FAULTCOND); 8=OCTL_23_CCPO_CC0_MIRROR_ALL (CC0_MIRROR_ALL); 9=OCTL_23_CCPO_CC1_MIRROR_ALL (CC1_MIRROR_ALL); 12=OCTL_23_CCPO_DEADBAND (DEADBAND); 13=OCTL_23_CCPO_CNTDIR (CNTDIR)
{0x1870+4i} CCACT_01[{i}] (i=0..1) — Capture or Compare Action Registers
  [31:30] CCACT_01_SWFRCACT_CMPL — CCP_CMPL Output Action on Software Froce Output This field describes the resulting action of software force. This action has a shadow register, which will be updated under specific condition. So that this register cannot take into effect immediately.
    0=CCACT_01_SWFRCACT_CMPL_DISABLED (DISABLED); 1=CCACT_01_SWFRCACT_CMPL_CCP_HIGH (CCP_HIGH); 2=CCACT_01_SWFRCACT_CMPL_CCP_LOW (CCP_LOW)
  [29:28] CCACT_01_SWFRCACT — CCP Output Action on Software Froce Output This field describes the resulting action of software force. This action has a shadow register, which will be updated under specific condition. So that this register cannot take into effect immediately.
    0=CCACT_01_SWFRCACT_DISABLED (DISABLED); 1=CCACT_01_SWFRCACT_CCP_HIGH (CCP_HIGH); 2=CCACT_01_SWFRCACT_CCP_LOW (CCP_LOW)
  [27:25] CCACT_01_FEXACT — CCP Output Action on Fault Exit This field describes the resulting action of the signal generator upon exiting the fault condition.
    0=CCACT_01_FEXACT_DISABLED (DISABLED); 1=CCACT_01_FEXACT_CCP_HIGH (CCP_HIGH); 2=CCACT_01_FEXACT_CCP_LOW (CCP_LOW); 3=CCACT_01_FEXACT_CCP_TOGGLE (CCP_TOGGLE); 4=CCACT_01_FEXACT_CCP_HIGHZ (CCP_HIGHZ)
  [24:22] CCACT_01_FENACT — CCP Output Action on Fault Entry This field describes the resulting action of the signal generator upon detecting a fault.
    0=CCACT_01_FENACT_DISABLED (DISABLED); 1=CCACT_01_FENACT_CCP_HIGH (CCP_HIGH); 2=CCACT_01_FENACT_CCP_LOW (CCP_LOW); 3=CCACT_01_FENACT_CCP_TOGGLE (CCP_TOGGLE); 4=CCACT_01_FENACT_CCP_HIGHZ (CCP_HIGHZ)
  [16:15] CCACT_01_CC2UACT — CCP Output Action on CC2U event.
    0=CCACT_01_CC2UACT_DISABLED (DISABLED); 1=CCACT_01_CC2UACT_CCP_HIGH (CCP_HIGH); 2=CCACT_01_CC2UACT_CCP_LOW (CCP_LOW); 3=CCACT_01_CC2UACT_CCP_TOGGLE (CCP_TOGGLE)
  [13:12] CCACT_01_CC2DACT — CCP Output Action on CC2D event.
    0=CCACT_01_CC2DACT_DISABLED (DISABLED); 1=CCACT_01_CC2DACT_CCP_HIGH (CCP_HIGH); 2=CCACT_01_CC2DACT_CCP_LOW (CCP_LOW); 3=CCACT_01_CC2DACT_CCP_TOGGLE (CCP_TOGGLE)
  [10:9] CCACT_01_CUACT — CCP Output Action on Compare (Up) This field describes the resulting action of the signal generator upon detecting a compare event while counting up.
    0=CCACT_01_CUACT_DISABLED (DISABLED); 1=CCACT_01_CUACT_CCP_HIGH (CCP_HIGH); 2=CCACT_01_CUACT_CCP_LOW (CCP_LOW); 3=CCACT_01_CUACT_CCP_TOGGLE (CCP_TOGGLE)
  [7:6] CCACT_01_CDACT — CCP Output Action on Compare (Down) This field describes the resulting action of the signal generator upon detecting a compare event while counting down.
    0=CCACT_01_CDACT_DISABLED (DISABLED); 1=CCACT_01_CDACT_CCP_HIGH (CCP_HIGH); 2=CCACT_01_CDACT_CCP_LOW (CCP_LOW); 3=CCACT_01_CDACT_CCP_TOGGLE (CCP_TOGGLE)
  [4:3] CCACT_01_LACT — CCP Output Action on Load Specifies what changes occur to CCP output as the result of a load event.
    0=CCACT_01_LACT_DISABLED (DISABLED); 1=CCACT_01_LACT_CCP_HIGH (CCP_HIGH); 2=CCACT_01_LACT_CCP_LOW (CCP_LOW); 3=CCACT_01_LACT_CCP_TOGGLE (CCP_TOGGLE)
  [1:0] CCACT_01_ZACT — CCP Output Action on Zero Specifies what changes occur to CCP output as the result of a zero event.
    0=CCACT_01_ZACT_DISABLED (DISABLED); 1=CCACT_01_ZACT_CCP_HIGH (CCP_HIGH); 2=CCACT_01_ZACT_CCP_LOW (CCP_LOW); 3=CCACT_01_ZACT_CCP_TOGGLE (CCP_TOGGLE)
{0x1878+4i} CCACT_23[{i}] (i=0..1) — Capture or Compare Action Registers
  [31:30] CCACT_23_SWFRCACT_CMPL — CCP_CMPL Output Action on Software Froce Output This field describes the resulting action of software force. This action has a shadow register, which will be updated under specific condition. So that this register cannot take into effect immediately.
    0=CCACT_23_SWFRCACT_CMPL_DISABLED (DISABLED); 1=CCACT_23_SWFRCACT_CMPL_CCP_HIGH (CCP_HIGH); 2=CCACT_23_SWFRCACT_CMPL_CCP_LOW (CCP_LOW)
  [29:28] CCACT_23_SWFRCACT — CCP Output Action on Software Froce Output This field describes the resulting action of software force. This action has a shadow register, which will be updated under specific condition. So that this register cannot take into effect immediately.
    0=CCACT_23_SWFRCACT_DISABLED (DISABLED); 1=CCACT_23_SWFRCACT_CCP_HIGH (CCP_HIGH); 2=CCACT_23_SWFRCACT_CCP_LOW (CCP_LOW)
  [27:25] CCACT_23_FEXACT — CCP Output Action on Fault Exit This field describes the resulting action of the signal generator upon exiting the fault condition.
    0=CCACT_23_FEXACT_DISABLED (DISABLED); 1=CCACT_23_FEXACT_CCP_HIGH (CCP_HIGH); 2=CCACT_23_FEXACT_CCP_LOW (CCP_LOW); 3=CCACT_23_FEXACT_CCP_TOGGLE (CCP_TOGGLE); 4=CCACT_23_FEXACT_CCP_HIGHZ (CCP_HIGHZ)
  [24:22] CCACT_23_FENACT — CCP Output Action on Fault Entry This field describes the resulting action of the signal generator upon detecting a fault.
    0=CCACT_23_FENACT_DISABLED (DISABLED); 1=CCACT_23_FENACT_CCP_HIGH (CCP_HIGH); 2=CCACT_23_FENACT_CCP_LOW (CCP_LOW); 3=CCACT_23_FENACT_CCP_TOGGLE (CCP_TOGGLE); 4=CCACT_23_FENACT_CCP_HIGHZ (CCP_HIGHZ)
  [16:15] CCACT_23_CC2UACT — CCP Output Action on CC2U event.
    0=CCACT_23_CC2UACT_DISABLED (DISABLED); 1=CCACT_23_CC2UACT_CCP_HIGH (CCP_HIGH); 2=CCACT_23_CC2UACT_CCP_LOW (CCP_LOW); 3=CCACT_23_CC2UACT_CCP_TOGGLE (CCP_TOGGLE)
  [13:12] CCACT_23_CC2DACT — CCP Output Action on CC2D event.
    0=CCACT_23_CC2DACT_DISABLED (DISABLED); 1=CCACT_23_CC2DACT_CCP_HIGH (CCP_HIGH); 2=CCACT_23_CC2DACT_CCP_LOW (CCP_LOW); 3=CCACT_23_CC2DACT_CCP_TOGGLE (CCP_TOGGLE)
  [10:9] CCACT_23_CUACT — CCP Output Action on Compare (Up) This field describes the resulting action of the signal generator upon detecting a compare event while counting up.
    0=CCACT_23_CUACT_DISABLED (DISABLED); 1=CCACT_23_CUACT_CCP_HIGH (CCP_HIGH); 2=CCACT_23_CUACT_CCP_LOW (CCP_LOW); 3=CCACT_23_CUACT_CCP_TOGGLE (CCP_TOGGLE)
  [7:6] CCACT_23_CDACT — CCP Output Action on Compare (Down) This field describes the resulting action of the signal generator upon detecting a compare event while counting down.
    0=CCACT_23_CDACT_DISABLED (DISABLED); 1=CCACT_23_CDACT_CCP_HIGH (CCP_HIGH); 2=CCACT_23_CDACT_CCP_LOW (CCP_LOW); 3=CCACT_23_CDACT_CCP_TOGGLE (CCP_TOGGLE)
  [4:3] CCACT_23_LACT — CCP Output Action on Load Specifies what changes occur to CCP output as the result of a load event.
    0=CCACT_23_LACT_DISABLED (DISABLED); 1=CCACT_23_LACT_CCP_HIGH (CCP_HIGH); 2=CCACT_23_LACT_CCP_LOW (CCP_LOW); 3=CCACT_23_LACT_CCP_TOGGLE (CCP_TOGGLE)
  [1:0] CCACT_23_ZACT — CCP Output Action on Zero Specifies what changes occur to CCP output as the result of a zero event.
    0=CCACT_23_ZACT_DISABLED (DISABLED); 1=CCACT_23_ZACT_CCP_HIGH (CCP_HIGH); 2=CCACT_23_ZACT_CCP_LOW (CCP_LOW); 3=CCACT_23_ZACT_CCP_TOGGLE (CCP_TOGGLE)
{0x1880+4i} IFCTL_01[{i}] (i=0..1) — Input Filter Control Register
  [12] IFCTL_01_FE — Filter Enable This bit controls whether the input is filtered by the input filter or bypasses to the edge detect.
    0=IFCTL_01_FE_DISABLED (DISABLED); 1=IFCTL_01_FE_ENABLED (ENABLED)
  [11] IFCTL_01_CPV — Consecutive Period/Voting Select This bit controls whether the input filter uses a stricter consecutive period count or majority voting.
    0=IFCTL_01_CPV_CONSECUTIVE (CONSECUTIVE); 1=IFCTL_01_CPV_VOTING (VOTING)
  [9:8] IFCTL_01_FP — Filter Period. This field specifies the sample period for the input filter. I.e. The input is sampled for FP timer clocks during filtering.
    0=IFCTL_01_FP__3 (_3); 1=IFCTL_01_FP__5 (_5); 2=IFCTL_01_FP__8 (_8)
  [7] IFCTL_01_INV — Input Inversion This bit controls whether the selected input is inverted.
    0=IFCTL_01_INV_NOINVERT (NOINVERT); 1=IFCTL_01_INV_INVERT (INVERT)
  [3:0] IFCTL_01_ISEL — Input Select (CCP0) This field selects the input source to the filter input. 4h-7h = Reserved
    0=IFCTL_01_ISEL_CCPX_INPUT (CCPX_INPUT); 1=IFCTL_01_ISEL_CCPX_INPUT_PAIR (CCPX_INPUT_PAIR); 2=IFCTL_01_ISEL_CCP0_INPUT (CCP0_INPUT); 3=IFCTL_01_ISEL_TRIG_INPUT (TRIG_INPUT); 4=IFCTL_01_ISEL_CCP_XOR (CCP_XOR); 5=IFCTL_01_ISEL_FSUB0 (FSUB0); 6=IFCTL_01_ISEL_FSUB1 (FSUB1); 7=IFCTL_01_ISEL_COMP0 (COMP0); 8=IFCTL_01_ISEL_COMP1 (COMP1); 9=IFCTL_01_ISEL_COMP2 (COMP2)
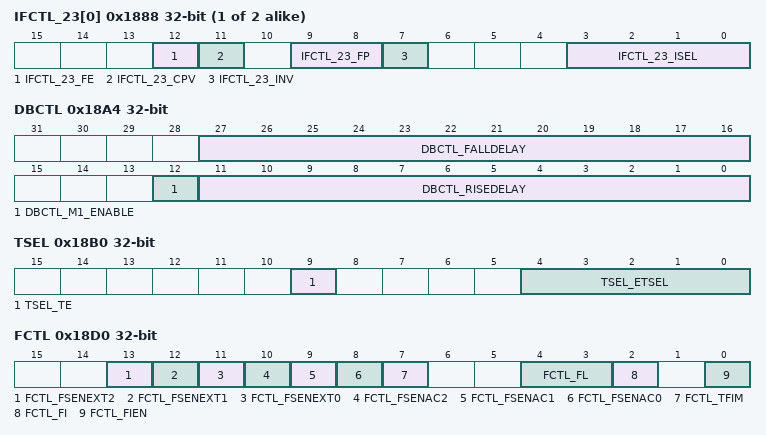
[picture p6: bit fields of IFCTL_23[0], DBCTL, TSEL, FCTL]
{0x1888+4i} IFCTL_23[{i}] (i=0..1) — Input Filter Control Register
  [12] IFCTL_23_FE — Filter Enable This bit controls whether the input is filtered by the input filter or bypasses to the edge detect.
    0=IFCTL_23_FE_DISABLED (DISABLED); 1=IFCTL_23_FE_ENABLED (ENABLED)
  [11] IFCTL_23_CPV — Consecutive Period/Voting Select This bit controls whether the input filter uses a stricter consecutive period count or majority voting.
    0=IFCTL_23_CPV_CONSECUTIVE (CONSECUTIVE); 1=IFCTL_23_CPV_VOTING (VOTING)
  [9:8] IFCTL_23_FP — Filter Period. This field specifies the sample period for the input filter. I.e. The input is sampled for FP timer clocks during filtering.
    0=IFCTL_23_FP__3 (_3); 1=IFCTL_23_FP__5 (_5); 2=IFCTL_23_FP__8 (_8)
  [7] IFCTL_23_INV — Input Inversion This bit controls whether the selected input is inverted.
    0=IFCTL_23_INV_NOINVERT (NOINVERT); 1=IFCTL_23_INV_INVERT (INVERT)
  [3:0] IFCTL_23_ISEL — Input Select (CCP0) This field selects the input source to the filter input. 4h-7h = Reserved
    0=IFCTL_23_ISEL_CCPX_INPUT (CCPX_INPUT); 1=IFCTL_23_ISEL_CCPX_INPUT_PAIR (CCPX_INPUT_PAIR); 2=IFCTL_23_ISEL_CCP0_INPUT (CCP0_INPUT); 3=IFCTL_23_ISEL_TRIG_INPUT (TRIG_INPUT); 4=IFCTL_23_ISEL_CCP_XOR (CCP_XOR); 5=IFCTL_23_ISEL_FSUB0 (FSUB0); 6=IFCTL_23_ISEL_FSUB1 (FSUB1); 7=IFCTL_23_ISEL_COMP0 (COMP0); 8=IFCTL_23_ISEL_COMP1 (COMP1); 9=IFCTL_23_ISEL_COMP2 (COMP2)
0x18A0 PL — Counter Register
  [15:0] PL_PHASE — Phase Load value
0x18A4 DBCTL — Dead Band insertion control register
  [27:16] DBCTL_FALLDELAY — Fall Delay The number of TIMCLK periods inserted between the fall of CCPi and the rise of CCPBo
  [12] DBCTL_M1_ENABLE — Dead Band Mode 1 Enable.
    0=DBCTL_M1_ENABLE_DISABLED (DISABLED); 1=DBCTL_M1_ENABLE_ENABLED (ENABLED)
  [11:0] DBCTL_RISEDELAY — Rise Delay The number of TIMCLK periods inserted between the fall of CCPi and the rise of CCPAo.
0x18B0 TSEL — Trigger Select
  [9] TSEL_TE — Trigger Enable. This selects whether a trigger is enabled or not for this counter 0x0 = Triggers are not used 0x1 = Triggers are used as selected by the ETSEL field
    0=TSEL_TE_DISABLED (DISABLED); 1=TSEL_TE_ENABLED (ENABLED)
  [4:0] TSEL_ETSEL — External Trigger Select. #br# This selects which System Event is used if the input filter selects trigger. Triggers 0-15 are used to connect triggers generated by other timer modules in the same power domain. Refer to the SoC datasheet to get details. Triggers 16 and 17 are connected to event manager subscriber ports. Event lines 18-31 are reserved for future use.
    {v}=TSEL_ETSEL_TRIG{v} (TRIG{v}) (v=0..15); 16=TSEL_ETSEL_TRIG_SUB0 (TRIG_SUB0); 17=TSEL_ETSEL_TRIG_SUB1 (TRIG_SUB1)
0x18B4 RC ro — Repeat counter
  [7:0] RC_RC — Repeat Counter Value
0x18B8 RCLD — Repeat counter
  [7:0] RCLD_RCLD — Repeat Counter Load Value This field provides the value loaded into the repeat counter at a load event following the repeat counter value equaling 0.
0x18D0 FCTL — Fault Control Register
  [13] FCTL_FSENEXT2 — Specifies whether the external fault pin3 fault sense is high or low active
    0=FCTL_FSENEXT2_LOWCTIVE (LOWCTIVE); 1=FCTL_FSENEXT2_HIGHACTIVE (HIGHACTIVE)
  [12] FCTL_FSENEXT1 — Specifies whether the external fault pin1 fault sense is high or low active
    0=FCTL_FSENEXT1_LOWCTIVE (LOWCTIVE); 1=FCTL_FSENEXT1_HIGHACTIVE (HIGHACTIVE)
  [11] FCTL_FSENEXT0 — Specifies whether the external fault pin0 sense is high or low active
    0=FCTL_FSENEXT0_LOWCTIVE (LOWCTIVE); 1=FCTL_FSENEXT0_HIGHACTIVE (HIGHACTIVE)
  [10] FCTL_FSENAC2 — Specifies whether the analog comparator2 fault sense is high or low active
    0=FCTL_FSENAC2_LOWCTIVE (LOWCTIVE); 1=FCTL_FSENAC2_HIGHACTIVE (HIGHACTIVE)
  [9] FCTL_FSENAC1 — Specifies whether the analog comparator1 fault sense is high or low active
    0=FCTL_FSENAC1_LOWCTIVE (LOWCTIVE); 1=FCTL_FSENAC1_HIGHACTIVE (HIGHACTIVE)
  [8] FCTL_FSENAC0 — Specifies whether the analog comparator0 fault sense is high or low active
    0=FCTL_FSENAC0_LOWCTIVE (LOWCTIVE); 1=FCTL_FSENAC0_HIGHACTIVE (HIGHACTIVE)
  [7] FCTL_TFIM — Trigger Fault Input Mask Specifies whether the selected trigger participates as a fault input. If enabled and the trigger asserts, the trigger is treated as a fault.
    0=FCTL_TFIM_DISABLED (DISABLED); 1=FCTL_TFIM_ENABLED (ENABLED)
  [4:3] FCTL_FL — Fault Latch mode Specifies whether the fault condition is latched and configures the latch clear conditions.
    0=FCTL_FL_NO_LATCH (NO_LATCH); 1=FCTL_FL_LATCH_SW_CLR (LATCH_SW_CLR); 2=FCTL_FL_LATCH_Z_CLR (LATCH_Z_CLR); 3=FCTL_FL_LATCH_LD_CLR (LATCH_LD_CLR)
  [2] FCTL_FI — Fault Input Specifies whether the overall fault condition is dependent on the sensed fault pin.
    0=FCTL_FI_INDEPENDENT (INDEPENDENT); 1=FCTL_FI_DEPENDENT (DEPENDENT)
  [0] FCTL_FIEN — Fault Input Enable This bit enables the input for fault detection.
    0=FCTL_FIEN_DISABLED (DISABLED); 1=FCTL_FIEN_ENABLED (ENABLED)
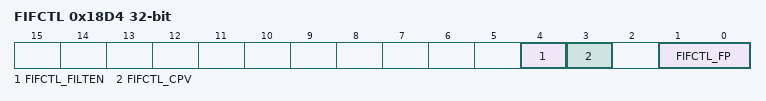
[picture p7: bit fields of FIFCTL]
0x18D4 FIFCTL — Fault input Filter control register
  [4] FIFCTL_FILTEN — Filter Enable This bit controls whether the input is filtered by the input filter or bypasses to go directly to the optional pre-scale filter and then to the edge detect.
    0=FIFCTL_FILTEN_BYPASS (BYPASS); 1=FIFCTL_FILTEN_FILTERED (FILTERED)
  [3] FIFCTL_CPV — Consecutive Period/Voting Select This bit controls whether the input filter uses a stricter consecutive period count or majority voting.
    0=FIFCTL_CPV_CONSEC_PER (CONSEC_PER); 1=FIFCTL_CPV_VOTING (VOTING)
  [1:0] FIFCTL_FP — Filter Period This field specifies the sample period for the input filter. I.e. The input is sampled for FP timer clocks during filtering.
    0=FIFCTL_FP_PER_3 (PER_3); 1=FIFCTL_FP_PER_5 (PER_5); 2=FIFCTL_FP_PER_8 (PER_8)
